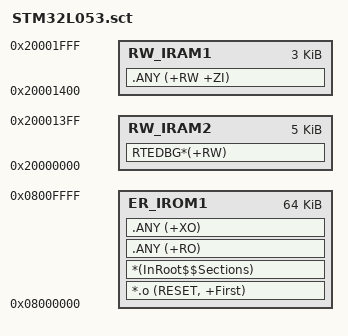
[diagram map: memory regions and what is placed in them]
; *************************************************************
; *** Scatter-Loading Description File generated by uVision ***
; *************************************************************

LR_IROM1 0x08000000 0x00010000  {    ; load region size_region
  ER_IROM1 0x08000000 0x00010000 {   ; load address = execution address
   *.o (RESET, +First)
   *(InRoot$$Sections)
   .ANY (+RO)
   .ANY (+XO)
  }
  RW_IRAM1 0x20001400 0x00000C00  {  ; RW data
   .ANY (+RW +ZI)
  }
  RW_IRAM2 0x20000000 0x00001400  {  ; RW data for the RTEdbg structure
    RTEDBG*(+RW)
  }
}
